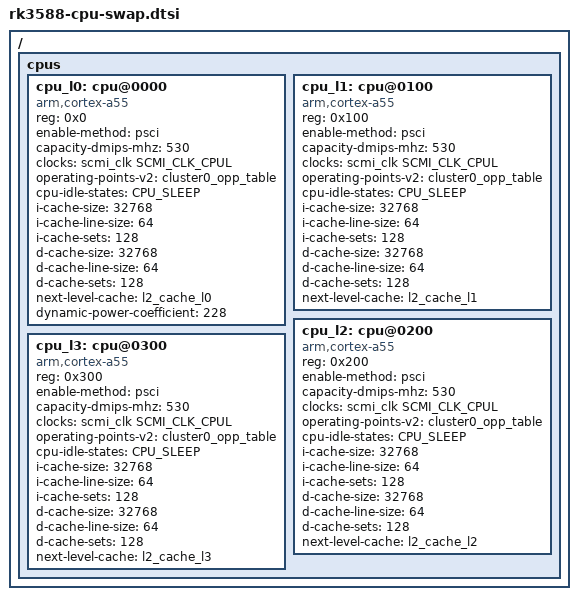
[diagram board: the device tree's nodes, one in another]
// SPDX-License-Identifier: (GPL-2.0+ OR MIT)
/*
 * Copyright (c) 2022 Rockchip Electronics Co., Ltd.
 */

/delete-node/ &cpu_l0;
/delete-node/ &cpu_l1;
/delete-node/ &cpu_l2;
/delete-node/ &cpu_l3;

/ {
	cpus {
		cpu_l0: cpu@0000 {
			device_type = "cpu";
			compatible = "arm,cortex-a55";
			reg = <0x0>;
			enable-method = "psci";
			capacity-dmips-mhz = <530>;
			clocks = <&scmi_clk SCMI_CLK_CPUL>;
			operating-points-v2 = <&cluster0_opp_table>;
			cpu-idle-states = <&CPU_SLEEP>;
			i-cache-size = <32768>;
			i-cache-line-size = <64>;
			i-cache-sets = <128>;
			d-cache-size = <32768>;
			d-cache-line-size = <64>;
			d-cache-sets = <128>;
			next-level-cache = <&l2_cache_l0>;
			#cooling-cells = <2>;
			dynamic-power-coefficient = <228>;
		};

		cpu_l1: cpu@0100 {
			device_type = "cpu";
			compatible = "arm,cortex-a55";
			reg = <0x100>;
			enable-method = "psci";
			capacity-dmips-mhz = <530>;
			clocks = <&scmi_clk SCMI_CLK_CPUL>;
			operating-points-v2 = <&cluster0_opp_table>;
			cpu-idle-states = <&CPU_SLEEP>;
			i-cache-size = <32768>;
			i-cache-line-size = <64>;
			i-cache-sets = <128>;
			d-cache-size = <32768>;
			d-cache-line-size = <64>;
			d-cache-sets = <128>;
			next-level-cache = <&l2_cache_l1>;
		};

		cpu_l2: cpu@0200 {
			device_type = "cpu";
			compatible = "arm,cortex-a55";
			reg = <0x200>;
			enable-method = "psci";
			capacity-dmips-mhz = <530>;
			clocks = <&scmi_clk SCMI_CLK_CPUL>;
			operating-points-v2 = <&cluster0_opp_table>;
			cpu-idle-states = <&CPU_SLEEP>;
			i-cache-size = <32768>;
			i-cache-line-size = <64>;
			i-cache-sets = <128>;
			d-cache-size = <32768>;
			d-cache-line-size = <64>;
			d-cache-sets = <128>;
			next-level-cache = <&l2_cache_l2>;
		};

		cpu_l3: cpu@0300 {
			device_type = "cpu";
			compatible = "arm,cortex-a55";
			reg = <0x300>;
			enable-method = "psci";
			capacity-dmips-mhz = <530>;
			clocks = <&scmi_clk SCMI_CLK_CPUL>;
			operating-points-v2 = <&cluster0_opp_table>;
			cpu-idle-states = <&CPU_SLEEP>;
			i-cache-size = <32768>;
			i-cache-line-size = <64>;
			i-cache-sets = <128>;
			d-cache-size = <32768>;
			d-cache-line-size = <64>;
			d-cache-sets = <128>;
			next-level-cache = <&l2_cache_l3>;
		};
	};
};
